# ECD3_MMR_ICONT register map
Vendor: Texas Instruments
Registers are 32-bit, access per field, reset 0x0 unless marked. A register's access mark holds for its fields unless they carry their own. Offsets are as the file gives them; [hi:lo] are bit positions.

## ECD3_MMR_ICONT (part 2 of 2)
0x00 ECD_PID ro reset not defined — Product Identification
  [31:0] PID — Displays the product identification code.
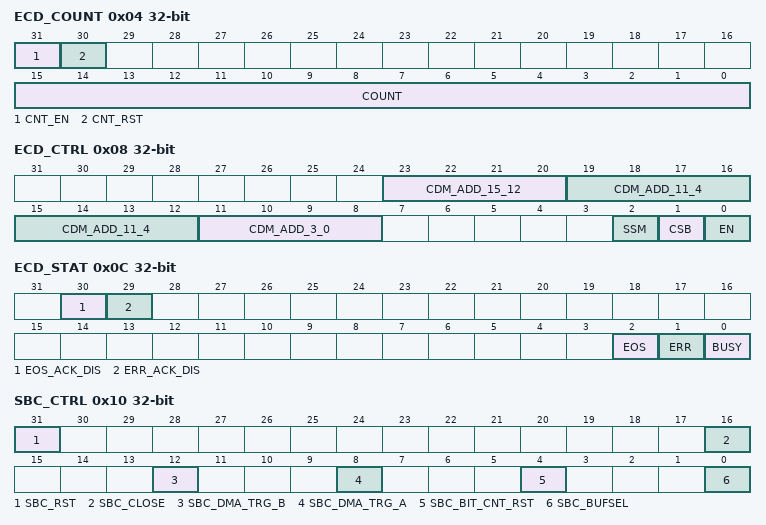
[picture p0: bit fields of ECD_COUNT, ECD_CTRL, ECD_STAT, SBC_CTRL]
0x04 ECD_COUNT — Cycle Counter
  [31] CNT_EN rw — Write 0x0: Disable the cycle counter. Write 0x1: Enable the cycle counter. While ECD_COUNT[31] CNT_EN = 0x1 and ECD_CTRL[0] EN = 0x1, the ECD3 increments the value of ECD_COUNT[15:0] COUNT for each cycle.
  [30] CNT_RST wo — Resets the cycle counter COUNT value to 0. Write 0x1: Clears COUNT. Write 0x0: No effect. Reads returns 0.
  [15:0] COUNT ro — Displays the current counter value.
0x08 ECD_CTRL (reset mask 0xFFFFFFFB) — Control
  [23:20] CDM_ADD_15_12 ro — Specifies the starting byte address [15:12] of command sequence stored in ECDABUF. Note that LSB 4 bits are fixed to 0 since command codes are to be stored from an 16-byte aligned position. ECD3 reads and executes commands in a linear order from this address.
  [19:12] CDM_ADD_11_4 rw — Specifies the starting byte address [11:4] of command sequence stored in ECDABUF. Note that LSB 4 bits are fixed to 0 since command codes are to be stored from an 16-byte aligned position. ECD3 reads and executes commands in a linear order from this address.
  [11:8] CDM_ADD_3_0 ro — Specifies the starting byte address [3:0] of command sequence stored in ECDABUF. Note that LSB 4 bits are fixed to 0 since command codes are to be stored from an 16-byte aligned position. ECD3 reads and executes commands in a linear order from this address.
  [2] SSM rw — 0x1: Enable single command mode. In single command mode, the ECD3 core executes only one command.
  [1] CSB ro — Read 0x1: Indicates that ECD3 found an undefined op-code during the last operation, and aborted command processing. Read 0x0: Indicates that the last command processing ended normally with an END command.
  [0] EN rw — Write 0x1: ECD3 starts operation (command processing), and EN stays 1 until ECD3 ends its operation. When ECD3 ends its operation, EN is turned to 0 by the ECD3. While EN = 1, no write access to ECD_CTRL is allowed. If ECD_CTRL is written while EN = 1, the result is unknown.
0x0C ECD_STAT — ECD Status
  [30] EOS_ACK_DIS rw — Read 0x1: Indicates that the EOS interrupt handshake between ECD3 and SYNCBOX is disabled and the acknowledge signal is ignored. When it is disabled, the ECD3 does not wait for an acknowledge for EOS interrupt. Read 0x0: Indicates that ECD3 waits for an acknowledge from SYNCBOX after EOS is set to 1. The ECD3 stays BUSY state until the acknowledge or EOS is cleared.
  [29] ERR_ACK_DIS rw — Read 0x1: Indicates that the ERR interrupt handshake between ECD3 and SYNCBOX is disabled and the acknowledge signal is ignored. When it is disabled, the ECD3 does not wait for an acknowledge for ERR interrupt. Read 0x0: Indicates that ECD3 waits for an acknowledge from SYNCBOX after ERR is set to 1. The ECD3 stays BUSY state until the acknowledge or ERR is cleared.
  [2] EOS ro — Read 0x1: Indicates that the last macroblock is at the end of the slice. Write 0x0: Force to exit busy state while waiting for an acknowledge of EOS interrupt from SYNCBOX.
  [1] ERR ro — Read 0x1: Indicates an error was found in the stream while decoding. Write 0x0: Force to exit busy state while waiting for an acknowledge of ERR interrupt from SYNCBOX.
  [0] BUSY ro — Read 0x1: Indicates that ECD3 core is busy. This bit is set when EN bit in ECD_CTRL is set and is cleared when END command is executed.
0x10 SBC_CTRL — Stream Buffer Controller Control
  [31] SBC_RST wo — Resets the Stream Buffer Controller. Write 0x1: Resets all registers of Stream Buffer Controller (SBC) and brings it back to idle state. This has the same effect as hardware reset to SBC, but no effect to other part of ECD3 core. Write 0x0: No effect.
  [16] SBC_CLOSE wo — Close the bitstream data. When encoding: Write 0x1: Flushes bitstream data in Stream Buffer. Write 0x0: No effect When decoding: Write 0x1: Brings it back to idle state and discard bitstream data in the buffer. Write 0x0: No effect
  [12] SBC_DMA_TRG_B wo — Start DMA to fill empty page in the Buffer B manually. Write 0x1: Sends a DMA request for Buffer B.
  [8] SBC_DMA_TRG_A wo — Start DMA to fill empty page in the Buffer A manually. Write 0x1: Sends a DMA request for Buffer A.
  [4] SBC_BIT_CNT_RST wo — Reset bit counter in the Stream Buffer.
  [0] SBC_BUFSEL rw — Selects active buffer between A and B: Write 0x0: Buffer A is selected Write 0x1: Buffer B is selected This bit is ignored if SBC_BUFCFG[24] SBC_DBL = 0. If SBC_BUFCFG[24] SBC_DBL = 0, buffer A is always selected.
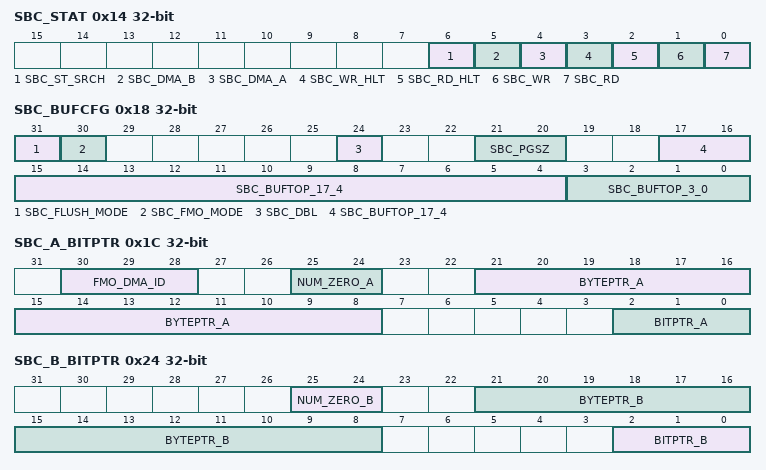
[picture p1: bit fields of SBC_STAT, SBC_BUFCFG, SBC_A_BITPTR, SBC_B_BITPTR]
0x14 SBC_STAT access not given — Stream Buffer Controller Status
  [6] SBC_ST_SRCH ro — Read 0x1: Indicates that the Stream Buffer Controller searching start code by request from codec engine. This bit is cleared when start code is found or page counter value reaches SBC_SRCH_PG_CNT.
  [5] SBC_DMA_B — Read 0x1: Indicates that the Stream Buffer Controller is waiting an acknowledge from DMA for buffer B. Write 0x0: Force to exit busy state while waiting for an acknowledge of DMA for buffer B interrupt from SYNCBOX. (access RW W0toClr)
  [4] SBC_DMA_A — Read 0x1: Indicates that the Stream Buffer Controller is waiting an acknowledge from DMA for buffer A. Write 0x0: Force to exit busy state while waiting for an acknowledge of DMA for buffer A interrupt from SYNCBOX. (access RW W0toClr)
  [3] SBC_WR_HLT ro — Read 0x1: Indicates that the Stream Buffer Controller halted while writing (encoding) and is waiting an acknowledge from DMA. If SBC_WR_HLT = 1, SBC_DMA_A or SBC_DMA_B must also be asserted.
  [2] SBC_RD_HLT ro — Read 0x1: Indicates that the Stream Buffer Controller halted while reading (decoding) and is waiting an acknowledge from DMA.
  [1] SBC_WR ro — Read 0x1: Indicates that the Stream Buffer Controller is in writing (encoding) mode.
  [0] SBC_RD ro — Read 0x1: Indicates that the Stream Buffer Controller is in reading (decoding) mode.
0x18 SBC_BUFCFG — Stream Buffer Controller Buffer Configuration
  [31] SBC_FLUSH_MODE rw — SBC FIFO flush mode select for encoding. Write 0x0: Flush FIFO when EOS flag is sent by Codec Engine Write 0x1: Flush FIFO when DONE or EOS flag is sent by Codec Engine. (This is for debug)
  [30] SBC_FMO_MODE rw — SBC FIFO flush mode select for encoding. Write 0x0: Buffer A and B pointers are used for Stream Data access. SBC_A_BITPTR[30:28] FMO_DMA_ID will be ignored. Write 0x1: Buffer A pointer and SBC_A_BITPTR[30:28] FMO_DMA_ID are used for Stream Data access.
  [24] SBC_DBL rw — Enables double buffer mode. Write 0x0: disabled (buffer A only mode) Write 0x1: enabled (buffer A and buffer B).
  [21:20] SBC_PGSZ rw — Specifies the page size of buffer A and B in the unit of 1024 [byte]. If SBC_PGSZ = 0, it is treated as though SBC_PGSZ = 4 that is, the page size is set to 4096 [byte].
  [17:4] SBC_BUFTOP_17_4 rw — Specifies the base address [17:4] of the bitstream buffer in SL2. Note that the LSB 4 bits are fixed to 0 because of the 128-bit alignment of the buffer area.
  [3:0] SBC_BUFTOP_3_0 ro — Specifies the base address [3:0] of the bitstream buffer in SL2. Note that the LSB 4 bits are fixed to 0 because of the 128-bit alignment of the buffer area.
0x1C SBC_A_BITPTR — Stream Buffer Controller A Bit Pointer
  [30:28] FMO_DMA_ID rw — Indicates the ID number of bitstream data in SL2 memory. The ID number is applied to SBC_FMO_DMA_STAT[7:0] FMO_DMA. This ID is valid when SBC_BUFCFG[30] SBC_FMO_MODE=1.
  [25:24] NUM_ZERO_A rw — Indicates the number of 0 bytes in the past for buffer A. This is used for emulation prevention byte manipulation. Note that the counting 0 bytes in decoding is different from that in encoding. 0 &lt;= NUM_ZERO_A &lt;= 2. This bit field is not updated when JPEG is selected by CDC_MODE. This bit field setting must match with actual bitstream data. If it does not match, EPB or EPC may be inserted or removed wrongly. This bit field is used only for H.264, VC-1 and AVS.
  [21:8] BYTEPTR_A rw — Indicates the current byte offset address in Buffer A of the byte containing the next bit in the bitstream. 0 &lt;= BYTEPTR_A &lt; 2 * (page size).
  [2:0] BITPTR_A rw — Indicates the next bit position in the byte at BYTEPTR_A. 0 &lt;= BITPTR_A &lt;= 7.
0x20 SBC_A_DMAPG — Stream Buffer Controller A DMA Page
  [7:0] DMAPG_A rw — Indicates the page that is being accessed from DMA for bitstream data transferring. If DMA is not accessing to the buffer, this register indicates the page that is currently being accessed from ECD3 core. The state is toggled by DMA task complete acknowledge (ack_strm_a).
0x24 SBC_B_BITPTR — Stream Buffer Controller B Bit Pointer
  [25:24] NUM_ZERO_B rw — Indicates the number of 0 bytes in the past for buffer B. This is used for emulation prevention byte manipulation. Note that the counting 0 bytes in decoding is different from that in encoding. 0 &lt;= NUM_ZERO_B &lt;= 2. This bit field is not updated when JPEG is selected by CDC_MODE. This bit field setting must match with actual bitstream data. If it does not match, EPB or EPC may be inserted or removed wrongly. This bit field is used only for H.264, VC-1 and AVS.
  [21:8] BYTEPTR_B rw — Indicates the current byte offset address in Buffer B of the byte containing the next bit in the bitstream. 0 &lt;= BYTEPTR_B &lt; 2 * (page size).
  [2:0] BITPTR_B rw — Indicates the next bit position in the byte at BYTEPTR_B. 0 &lt;= BITPTR_B &lt;= 7.
0x28 SBC_B_DMAPG — Stream Buffer Controller B DMA Page
  [0] DMAPG_B rw — Indicates the page that is being accessed from DMA for bitstream data transferring. If DMA is not accessing to the buffer, this register indicates the page that is currently being accessed from ECD3 core. This bit is toggled by DMA task complete acknowledge (ack_strm_b).
0x2C SBC_TTLCNT rw — Stream Buffer Controller Total Bit Counter
  [31:0] TTLCNT — Displays the total bit count. This counter does not count during start code searching.
0x30 SBC_RSDCNT rw — Stream Buffer Controller Residual Layer Bit Counter
  [31:0] SBC_RSDCNT — Displays the bit count for residual layer. Total bit count - header info = residual data (transform coefficients)
0x38 SBC_SRCH_PG_CNT — Buffer page counter for start code searching.
  [15:0] SRCH_PG_CNT rw — ECD3 search start code until the page counter reach this number. If the start code is not found, error pulse is sent to codec engine and codec engine stop operation then generates an error interrupt.
0x3C SBC_FMO_DMA_STAT access not given — FMO_DMA status register
  [7:0] FMO_DMA — Indicates FMO_DMA_ID for stream interrupt at buffer page boundary. FMO_DMA_ID range is 0 to 7. When the interrupt is asserted, corresponding bit is set. Write 0 to clear the flag. Writing 1 does not affect this register. (access RW W0toClr)
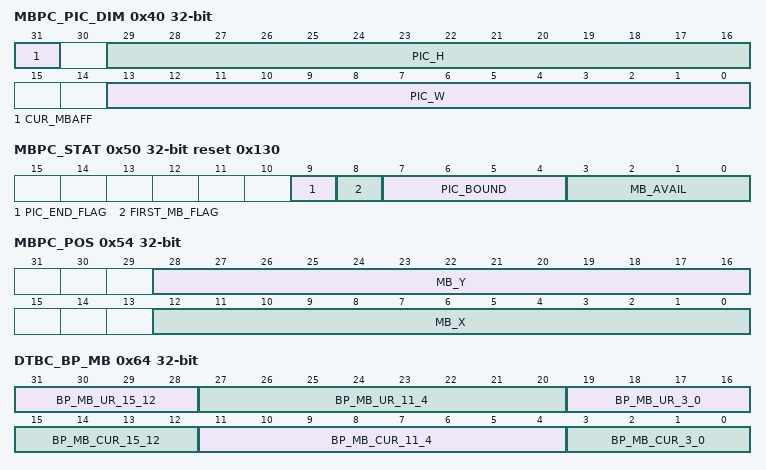
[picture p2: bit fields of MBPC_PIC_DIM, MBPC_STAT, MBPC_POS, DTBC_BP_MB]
0x40 MBPC_PIC_DIM — Picture Dimension
  [31] CUR_MBAFF rw — CUR_MBAFF = 1 indicates that current picture is in H.264 MBAFF mode.
  [29:16] PIC_H rw — PIC_H specifies the picture height in macroblocks which is calculated by PIC_H = ((picture height in pixels) + 15)/16. 0 &lt; PIC_H &lt;= 8192. All codec maximum picture height in pixels is 4096 (PIC_H = 256) except JPEG.
  [13:0] PIC_W rw — PIC_W specifies the picture width in macroblocks which is calculated by PIC_W = ((picture width in pixels) + 15)/16. 0 &lt; PIC_W &lt;= 8192. All codec maximum picture width in pixels is 4096 (PIC_W = 256) except JPEG.
0x50 MBPC_STAT reset 0x130 — MB Position Controller Status
  [9] PIC_END_FLAG rw — PIC_END_FLAG = 1 indicates that the macroblock will be processed is at the end of the picture. (In other words, this field is set to 1 before last MB process execution.)
  [8] FIRST_MB_FLAG rw — FIRST_MB_FLAG = 1 indicates that the macroblock will be processed is the first macroblock in the slice. (In other words, this field is set to 1 after last MB process execution.)
  [7:4] PIC_BOUND rw — PIC_BOUND indicates that the picture boundary status of the current macroblock (in case of MBAFF mode, the unit is macroblock-pair). PIC_BOUND[0] = 1 indicates that the left macroblock edge is an picture boundary. PIC_BOUND[1] = 1 indicates that the upper edge is an picture boundary. PIC_BOUND[2] = 1 indicates that the right edge is an picture boundary. PIC_BOUND[3] = 1 indicates that the bottom edge is an picture boundary.
  [3:0] MB_AVAIL rw — MB_AVAIL indicates that the availabilities of neighboring macroblocks (in case of MBAFF mode, the unit is macroblock-pair). MB_AVAIL[0] : left macroblock, MB_AVAIL[1] : upper left macroblock, MB_AVAIL[2] : upper macroblock, MB_AVAIL[3] :.upper-right macroblock.
0x54 MBPC_POS — Macroblock Position
  [28:16] MB_Y rw — MB_Y equals the macroblock y-position in the picture. 0 &lt;= MB_Y &lt; PIC_H. All codec maximum MB Y position is 255 except JPEG.
  [12:0] MB_X rw — MB_X equals the macroblock x-position in the picture. 0 &lt;= MB_X &lt; PIC_W. All codec maximum MB X position is 255 except JPEG.
0x58 MBPC_PMC — Macroblock Count In Picture
  [25:0] PIC_MB_CNT rw — PIC_MB_CNT equals the macroblock count in the picture. 0 &lt;= PIC_MB_CNT &lt; (PIC_W * PIC_H).
0x5C MBPC_SMC — Macroblock Count In Slice
  [25:0] SLC_MB_CNT rw — SLC_MB_CNT equals the macroblock count in the slice. 0 &lt;= SLC_MB_CNT &lt; (PIC_W * PIC_H).
0x64 DTBC_BP_MB — Data Buffer Controller MB Base Buffer Pointer
  [31:28] BP_MB_UR_15_12 ro — BP_MB_UR specifies the base pointer to the upper macroblock buffer. 0x8000-0x8FFF.
  [27:20] BP_MB_UR_11_4 rw — BP_MB_UR specifies the base pointer to the upper macroblock buffer. 0x8000-0x8FFF.
  [19:16] BP_MB_UR_3_0 ro — BP_MB_UR specifies the base pointer to the upper macroblock buffer. 0x8000-0x8FFF.
  [15:12] BP_MB_CUR_15_12 ro — BP_MB_CUR specifies the base pointer to the current macroblock buffer. 0x8000-0x8FFF.
  [11:4] BP_MB_CUR_11_4 rw — BP_MB_CUR specifies the base pointer to the current macroblock buffer. 0x8000-0x8FFF.
  [3:0] BP_MB_CUR_3_0 ro — BP_MB_CUR specifies the base pointer to the current macroblock buffer. 0x8000-0x8FFF.
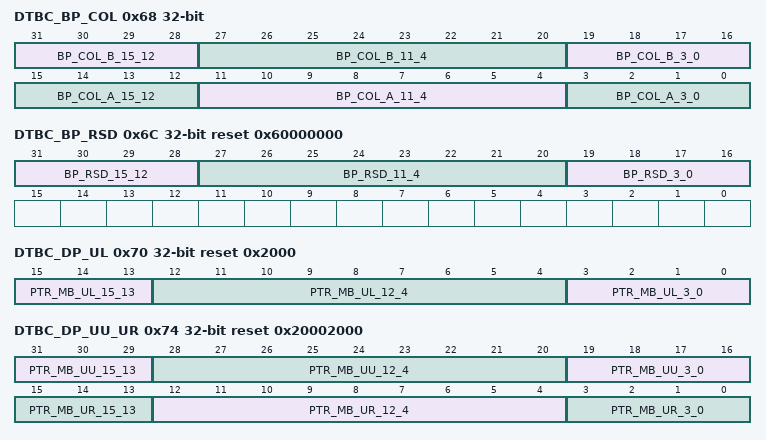
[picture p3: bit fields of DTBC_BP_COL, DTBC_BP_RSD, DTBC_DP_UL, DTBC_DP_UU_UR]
0x68 DTBC_BP_COL — Data Buffer Controller Co-located MB Buffer Base Pointer
  [31:28] BP_COL_B_15_12 ro — BP_COL_B specifies the base pointer to the co-located macroblock buffer B. 0x8000-0x8FFF.
  [27:20] BP_COL_B_11_4 rw — BP_COL_B specifies the base pointer to the co-located macroblock buffer B. 0x8000-0x8FFF.
  [19:16] BP_COL_B_3_0 ro — BP_COL_B specifies the base pointer to the co-located macroblock buffer B. 0x8000-0x8FFF.
  [15:12] BP_COL_A_15_12 ro — BP_COL_A specifies the base pointer to the co-located macroblock buffer A. 0x8000-0x8FFF.
  [11:4] BP_COL_A_11_4 rw — BP_COL_A specifies the base pointer to the co-located macroblock buffer A. 0x8000-0x8FFF.
  [3:0] BP_COL_A_3_0 ro — BP_COL_A specifies the base pointer to the co-located macroblock buffer A. 0x8000-0x8FFF.
0x6C DTBC_BP_RSD reset 0x60000000 — Data Buffer Controller Residual Buffer Base Pointer
  [31:28] BP_RSD_15_12 ro — BP_RSD specifies the base pointer to the residual data buffer. 0xE000-0xEFFF.
  [27:20] BP_RSD_11_4 rw — BP_RSD specifies the base pointer to the residual data buffer. 0xE000-0xEFFF.
  [19:16] BP_RSD_3_0 ro — BP_RSD specifies the base pointer to the residual data buffer. 0xE000-0xEFFF.
0x70 DTBC_DP_UL reset 0x2000 — Data Buffer Controller Data Pointer 0
  [15:13] PTR_MB_UL_15_13 ro — Current pointer [15:13] to the upper left macroblock data in work buffer. This pointer must be written before start ECD3.
  [12:4] PTR_MB_UL_12_4 rw — Current pointer [12:4] to the upper left macroblock data in work buffer. This pointer must be written before start ECD3.
  [3:0] PTR_MB_UL_3_0 ro — Current pointer [3:0] to the upper left macroblock data in work buffer. This pointer must be written before start ECD3.
0x74 DTBC_DP_UU_UR reset 0x20002000 — Data Buffer Controller Data Pointer 1
  [31:29] PTR_MB_UU_15_13 ro — Current pointer [15:13] to the upper macroblock data in work buffer. This pointer must be written before start ECD3.
  [28:20] PTR_MB_UU_12_4 rw — Current pointer [12:4] to the upper macroblock data in work buffer. This pointer must be written before start ECD3.
  [19:16] PTR_MB_UU_3_0 ro — Current pointer [3:0] to the upper macroblock data in work buffer. This pointer must be written before start ECD3.
  [15:13] PTR_MB_UR_15_13 ro — Current pointer [15:13] to the upper-right macroblock data in work buffer. This pointer must be written before start ECD3.
  [12:4] PTR_MB_UR_12_4 rw — Current pointer [12:4] to the upper-right macroblock data in work buffer. This pointer must be written before start ECD3.
  [3:0] PTR_MB_UR_3_0 ro — Current pointer [3:0] to the upper-right macroblock data in work buffer. This pointer must be written before start ECD3.
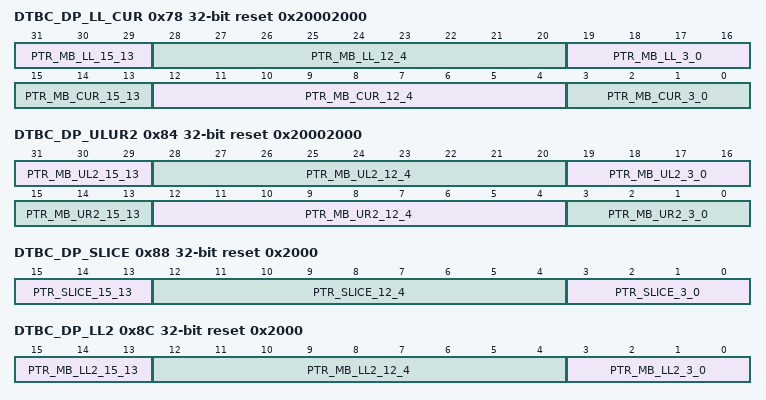
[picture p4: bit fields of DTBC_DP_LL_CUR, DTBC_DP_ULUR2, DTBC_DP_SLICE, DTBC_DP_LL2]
0x78 DTBC_DP_LL_CUR reset 0x20002000 — Data Buffer Controller Data Pointer 2
  [31:29] PTR_MB_LL_15_13 ro — Current pointer [15:13] to the left macroblock data in work buffer. This pointer must be written before start ECD3.
  [28:20] PTR_MB_LL_12_4 rw — Current pointer [12:4] to the left macroblock data in work buffer. This pointer must be written before start ECD3.
  [19:16] PTR_MB_LL_3_0 ro — Current pointer [3:0] to the left macroblock data in work buffer. This pointer must be written before start ECD3.
  [15:13] PTR_MB_CUR_15_13 ro — Current pointer [15:13] to the current macroblock data in work buffer. This pointer must be written before start ECD3.
  [12:4] PTR_MB_CUR_12_4 rw — Current pointer [12:4] to the current macroblock data in work buffer. This pointer must be written before start ECD3.
  [3:0] PTR_MB_CUR_3_0 ro — Current pointer [3:0] to the current macroblock data in work buffer. This pointer must be written before start ECD3.
0x84 DTBC_DP_ULUR2 reset 0x20002000 — Data Buffer Controller Data Pointer 5
  [31:29] PTR_MB_UL2_15_13 ro — Current pointer [15:13] to the macroblock left to the upper left macroblock data in work buffer. This pointer is maintained only for On2 (CDC_mode[3:0] MODE = 0x0A). This pointer must be written before start ECD3.
  [28:20] PTR_MB_UL2_12_4 rw — Current pointer [12:4] to the macroblock left to the upper left macroblock data in work buffer. This pointer is maintained only for On2 (CDC_mode[3:0] MODE = 0x0A). This pointer must be written before start ECD3.
  [19:16] PTR_MB_UL2_3_0 ro — Current pointer [3:0] to the macroblock left to the upper left macroblock data in work buffer. This pointer is maintained only for On2 (CDC_mode[3:0] MODE = 0x0A). This pointer must be written before start ECD3.
  [15:13] PTR_MB_UR2_15_13 ro — Current pointer [15:13] to the macroblock right to the upper-right macroblock data in work buffer. This pointer is maintained only for On2 (CDC_mode[3:0] MODE = 0x0A). This pointer must be written before start ECD3.
  [12:4] PTR_MB_UR2_12_4 rw — Current pointer [12:4] to the macroblock right to the upper-right macroblock data in work buffer. This pointer is maintained only for On2 (CDC_mode[3:0] MODE = 0x0A). This pointer must be written before start ECD3.
  [3:0] PTR_MB_UR2_3_0 ro — Current pointer [3:0] to the macroblock right to the upper-right macroblock data in work buffer. This pointer is maintained only for On2 (CDC_mode[3:0] MODE = 0x0A). This pointer must be written before start ECD3.
0x88 DTBC_DP_SLICE reset 0x2000 — Slice data pointer
  [15:13] PTR_SLICE_15_13 ro — Specifies the pointer [15:13] to slice or picture information data.
  [12:4] PTR_SLICE_12_4 rw — Specifies the pointer [12:4] to slice or picture information data.
  [3:0] PTR_SLICE_3_0 ro — Specifies the pointer [3:0] to slice or picture information data.
0x8C DTBC_DP_LL2 reset 0x2000 — Data Buffer Controller data pointer
  [15:13] PTR_MB_LL2_15_13 ro — Current pointer [15:13] to the macroblock left to the left macroblock data in work buffer. This pointer is maintained only for On2 (CDC_mode[3:0] MODE = 0x0A). This pointer must be written before start ECD3.
  [12:4] PTR_MB_LL2_12_4 rw — Current pointer [12:4] to the macroblock left to the left macroblock data in work buffer. This pointer is maintained only for On2 (CDC_mode[3:0] MODE = 0x0A). This pointer must be written before start ECD3.
  [3:0] PTR_MB_LL2_3_0 ro — Current pointer [3:0] to the macroblock left to the left macroblock data in work buffer. This pointer is maintained only for On2 (CDC_mode[3:0] MODE = 0x0A). This pointer must be written before start ECD3.
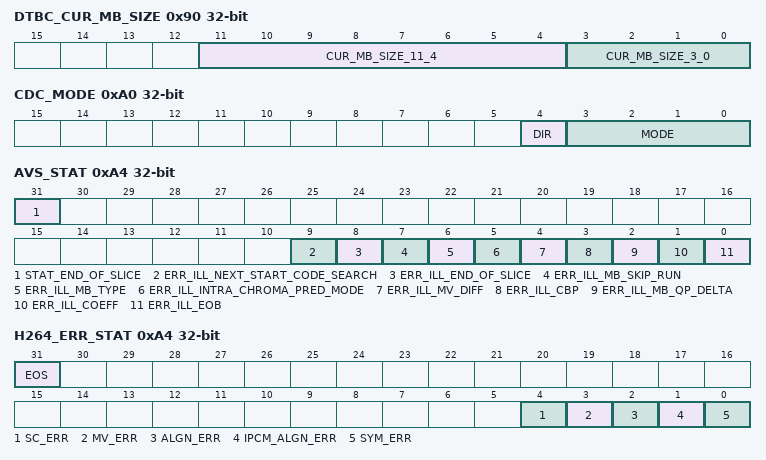
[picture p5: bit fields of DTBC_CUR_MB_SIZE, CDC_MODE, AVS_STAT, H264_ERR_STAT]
0x90 DTBC_CUR_MB_SIZE — Current Picture Macro Block element size
  [11:4] CUR_MB_SIZE_11_4 rw — Data element size for Current MB, Upper-right MB in AUX buffer and Upper MB, Current/Left MB in WORK buffer.
  [3:0] CUR_MB_SIZE_3_0 ro — Data element size for Current MB, Upper-right MB in AUX buffer and Upper MB, Current/Left MB in WORK buffer.
0xA0 CDC_MODE — Codec Mode (also works as view page).
  [4] DIR rw — Selects the codec direction: Write 0x0: Indicates the codec engine is decoding Write 0x1: Indicates the codec engine is encoding.
  [3:0] MODE rw — Selects the active codec Selected Codec (Selected Codec Engine)
    0=JPEG_(JPG); 1=N/A; 2=MPEG-1_(MP1); 3=MPEG-2_(MP2); 4=MPEG-4/H.263_(MP4); 5=VC-1_Advanced_(VC-1); 6=H.264_(H.264); 7=VC-1_Simple/Main_(VC-1); 8=AVS_(AVS); 9=RealVideo_(RV); 10=On2_VP6,VP7_(On2)
0xA4 AVS_STAT ro
  [31] STAT_END_OF_SLICE — stat_end_of_vop ECD sets this field to 1 when the current macroblock is the last macroblock in a VOP Once this field is set, ECD keeps this field to 1 until the next macroblock processing is started. ECD resets this field at the beginning of a macroblock processing
  [9] ERR_ILL_NEXT_START_CODE_SEARCH — err_ill_next_start_code_search If ECD founds error and ECD status is changed into ERR in error detection described in section 8.5., ECD starts to search the next start code search. But if ECD cannot find the start code until search counter reaches counter limit defined in the ECD3 core MMR, ECD fails start_code_search. In this case this flag is set to 1 by ECD; otherwise, 0
  [8] ERR_ILL_END_OF_SLICE — err_ill_end_of_slice Some encoder wrongly encode EOS. In this case this flag is set to 1 by ECD; otherwise, 0
  [7] ERR_ILL_MB_SKIP_RUN — err_ill_mb_skip_run If ECD founds decoded mb_skip_run is out of range, this field is set to 1 by ECD; otherwise, 0
  [6] ERR_ILL_MB_TYPE — err_ill_mb_type If ECD founds decoded mb_type is out of range, this field is set to 1 by ECD; otherwise, 0
  [5] ERR_ILL_INTRA_CHROMA_PRED_MODE — err_ill_intra_chroma_pred_mode If ECD founds decoded intra_chroma_pred_mode is out of range, this field is set to 1 by ECD; otherwise, 0
  [4] ERR_ILL_MV_DIFF — err_ill_mv_diff If ECD founds decoded mv_diff is out of range, this field is set to 1 by ECD; otherwise, 0
  [3] ERR_ILL_CBP — err_ill_cbp If ECD founds decoded cbp is out of range, this field is set to 1 by ECD; otherwise, 0
  [2] ERR_ILL_MB_QP_DELTA — err_ill_mb_qp_delta If ECD founds decoded mb_qp_delta is out of range, this field is set to 1 by ECD; otherwise, 0.
  [1] ERR_ILL_COEFF — err_ill_coeff If ECD founds decoded coefficient is out of range, this field is set to 1 by ECD; otherwise, 0
  [0] ERR_ILL_EOB — err_ill_eob If ECD cannot found end of block in 64 coefficients, this field is set to 1 by ECD; otherwise, 0.
0xA4 H264_ERR_STAT ro — H.264 STAT register
  [31] EOS — Read 0x1: Indicates that an EOS was found
  [4] SC_ERR — Read 0x1: Indicates that there was an error while searching the next start code. This error can only occur at the EOS where EOS=1.
  [3] MV_ERR — Read 0x1: Indicates that motion vector error was found in the last B-Direct motion vector calculation
  [2] ALGN_ERR — Read 0x1: Indicates that a zero bit was found in the last CABAC alignment bits
  [1] IPCM_ALGN_ERR — Read 0x1: Indicates that a non-zero bit was found in the last I_PCM alignment bits
  [0] SYM_ERR — Read 0x1: Indicates an illegal code word was found in the bitstream
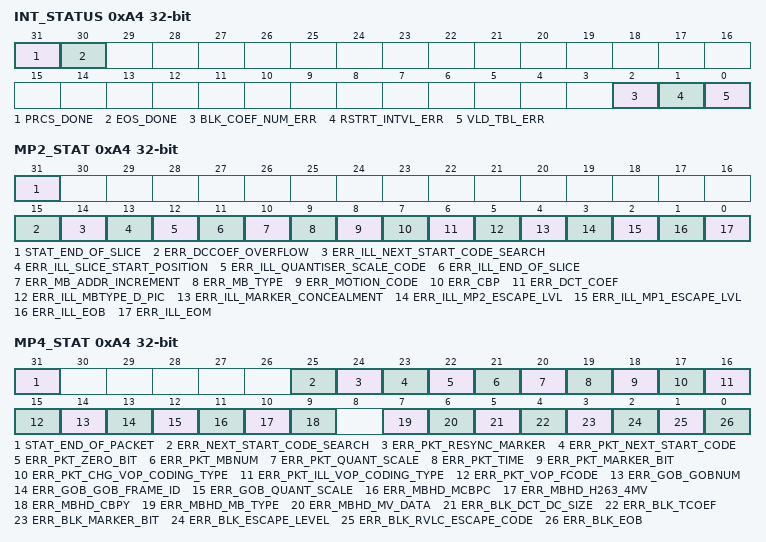
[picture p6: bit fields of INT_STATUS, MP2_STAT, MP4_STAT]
0xA4 INT_STATUS ro — INT STAT register
  [31] PRCS_DONE — If encoding or decoding of a picture is finished, an interrupt pulse is asserted and this status bit becomes high. It makes no sense to write 0 to this register bit. 0: not finished. 1: processing done
  [30] EOS_DONE — If encoding of decoding of a scan is finished, an interrupt pulse is asserted and this status bit becomes high. It makes no sense to write 0 to this register bit. 0: not finished. 1: processing done
  [2] BLK_COEF_NUM_ERR — If current MCU has a block which has more than 64 coefficients, this error bit becomes high. 0: correct (all blocks inside the current MCU have 64[coef/block]) 1: incorrect (some blocks inside the current MCU have more than 64[coef/block]).
  [1] RSTRT_INTVL_ERR — If number of MCU between neighbored restart markers is not equal to restart interval, this error bit becomes high. It makes no sense to write 0 to this register bit. 0: no error. 1: restart interval error occurs
  [0] VLD_TBL_ERR — If stream data which is out of table is detected, the JPEG core makes this bit high. It makes no sense to write 0 to this register bit. 0: no error. 1: out of table error occurs.
0xA4 MP2_STAT ro
  [31] STAT_END_OF_SLICE — Showing the current macroblock is the last macroblock in a slice. If STAT_END_OF_SLICE is set to 1, the ECD3 issues int_eos. Host can know whether ERR_ILL_NEXT_START_CODE_SEARCH and ERR_ILL_END_OF_SLICE are happened or not by looking MP2_STAT[14] and MP2_STAT[11] register fields when int_eos is issued.
  [15] ERR_DCCOEF_OVERFLOW — Showing the result of dc prediction is overflowed or under flowed
  [14] ERR_ILL_NEXT_START_CODE_SEARCH — Showing next start code searching infinite error. In decoding, next start code searching is started when: - the current macroblock is the last macroblock in a slice or - error is found w/start_code_search_flag is 1. During next start code searching, if search counter is over the limit of the counter, this field is set to 1. In encoding, this field is fixed to 0.
  [13] ERR_ILL_SLICE_START_POSITION — In decoding, showing the following two data is mismatched: - macroblock position derived from slice_vertical_position and macroblock_address_increment - macroblock position in ECD MMR In encoding, this field is fixed to 0.
  [12] ERR_ILL_QUANTISER_SCALE_CODE — In decoding, decoded quantizer_scale_code is 0. In encoding, this field is fixed to 0
  [11] ERR_ILL_END_OF_SLICE — In decoding, EOS cannot be found at the end of picture. In encoding, this field is fixed to 0.
  [10] ERR_MB_ADDR_INCREMENT — In decoding, VLD out of table in macroblock_address_increment. In encoding, this field is fixed to 0.
  [9] ERR_MB_TYPE — In decoding, VLD out of table in macroblock_type. In encoding, this field is fixed to 0.
  [8] ERR_MOTION_CODE — In decoding, VLD out of table in motion_code and dmv. In encoding, this field is fixed to 0.
  [7] ERR_CBP — In decoding, VLD out of table in coded_block_pattern. In encoding, this field is fixed to 0.
  [6] ERR_DCT_COEF — In decoding, VLD out of table in DCT coefficient. In encoding, this field is fixed to 0.
  [5] ERR_ILL_MBTYPE_D_PIC — In decoding, decoded macroblock_type != 1 when D-picture. In encoding, this field is fixed to 0.
  [4] ERR_ILL_MARKER_CONCEALMENT — In decoding, decoded marker_bit != 0 when both the concealment_motion_vector and macroblock_intra are equal to 1. In encoding, this field is fixed to 0.
  [3] ERR_ILL_MP2_ESCAPE_LVL — In decoding, decoded level from MPEG-2 ESCAPE code is 0x000 or 0x800. In encoding, this field is fixed to 0
  [2] ERR_ILL_MP1_ESCAPE_LVL — In decoding, decoded level from MPEG-1 ESCAPE code is 0x0000 or 0x8000. In encoding, this field is fixed to 0.
  [1] ERR_ILL_EOB — In decoding, ECD cannot find EOB, end of block, in a 64 coefficient block. In encoding, this field is fixed to 0.
  [0] ERR_ILL_EOM — In decoding, ECD cannot find EOM, end of macroblock, at the end of macroblock when picture_type is D-picture. In encoding, this field is fixed to 0.
0xA4 MP4_STAT ro
  [31] STAT_END_OF_PACKET — ECD sets this field to 1 when the current macroblock is the last macroblock in a packet. In the case of data partitioned, ECD issues the last macroblock of data partition 0, 1 and 2. Here, data partition 0 means the motion and header info processing, data partition 1 means texture header processing, and data partition 2 means the TCOEF processing. ECD resets this field at the beginning of a macroblock processing
  [25] ERR_NEXT_START_CODE_SEARCH — ECD sets this field to 1 if next start code search is 'failed'. 'Failed' means during next start code search, the search counter is over the limit of the counter which is in ECD3 SBC MMRs. Otherwise, ECD3 sets this field to 0. ECD sets this field the search counter is over the limit of the counter, this field is set to 1. Otherwise, 0.
  [24] ERR_PKT_RESYNC_MARKER — ECD sets this field to 1 when resync_marker at the beginning of packet header is incorrect. At the beginning of a processing, ECD automatically reset this field to 0. Even if ECD detects this error, ECD continues decoding until finishing the current macroblock processing
  [23] ERR_PKT_NEXT_START_CODE — ECD sets this field to 1 when next_start_code at the end of VOP is incorrect or start_code at the beginning of slice or at the end of VOP is incorrect. At the beginning of a processing, ECD automatically reset this field to 0. Even if ECD detects this error, ECD continues decoding until finishing the current macroblock processing
  [22] ERR_PKT_ZERO_BIT — ECD sets this field to 1 when zero_bit at the end of GOB or slice layer is incorrect or emulation_prevention_bit in slice header is incorrect. At the beginning of a processing, ECD automatically reset this field to 0. Even if ECD detects this error, ECD continues decoding until finishing the current macroblock processing
  [21] ERR_PKT_MBNUM — ECD sets this field to 1 when macroblock_number in packet header is dropped. At the beginning of a processing, ECD automatically reset this field to 0. Even if ECD detects this error, ECD continues decoding until finishing the current macroblock processing
  [20] ERR_PKT_QUANT_SCALE — ECD sets this field to 1 when quant_scale in packet header is illegal. At the beginning of a processing, ECD automatically reset this field to 0. Even if ECD detects this error, ECD continues decoding until finishing the current macroblock processing
  [19] ERR_PKT_TIME — ECD sets this field to 1 when modulo_time or vop_time_increment in packet header is changed. At the beginning of a processing, ECD automatically reset this field to 0. Even if ECD detects this error, ECD continues decoding until finishing the current macroblock processing
  [18] ERR_PKT_MARKER_BIT — ECD sets this field to 1 when marker_bit in packet header is incorrect. At the beginning of a processing, ECD automatically reset this field to 0. Even if ECD detects this error, ECD continues decoding until finishing the current macroblock processing
  [17] ERR_PKT_CHG_VOP_CODING_TYPE — ECD sets this field to 1 when vop_coding_type in packet header is changed. At the beginning of a processing, ECD automatically reset this field to 0. Even if ECD detects this error, ECD continues decoding until finishing the current macroblock processing
  [16] ERR_PKT_ILL_VOP_CODING_TYPE — ECD sets this field to 1 when vop_coding_type in packet header is illegal. At the beginning of a processing, ECD automatically reset this field to 0. Even if ECD detects this error, ECD continues decoding until finishing the current macroblock processing
  [15] ERR_PKT_VOP_FCODE — ECD sets this field to 1 when vop_fcode_forward or vop_fcode_backward in packet header is illegal. At the beginning of a processing, ECD automatically reset this field to 0. Even if ECD detects this error, ECD continues decoding until finishing the current macroblock processing
  [14] ERR_GOB_GOBNUM — ECD sets this field to 1 when gob_number is dropped or macroblock_address in slice header is dropped. At the beginning of a processing, ECD automatically reset this field to 0. Even if ECD detects this error, ECD continues decoding until finishing the current macroblock processing
  [13] ERR_GOB_GOB_FRAME_ID — ECD sets this field to 1 when gob_frame_id is changed. At the beginning of a processing, ECD automatically reset this field to 0. Even if ECD detects this error, ECD continues decoding until finishing the current macroblock processing
  [12] ERR_GOB_QUANT_SCALE — ECD sets this field to 1 when quant_scale in GOB header is illegal or slice_quantizer_information in slice header is illegal. At the beginning of a processing, ECD automatically resets this field to 0. Even if ECD detects this error, ECD continues decoding until finishing the current macroblock processing
  [11] ERR_MBHD_MCBPC — ECD sets this field to 1 when mcbpc code is illegal. At the beginning of a processing, ECD automatically reset this field to 0. If ECD detects this error, if data_partitioned is ON, ECD continues decoding the current DP0 or DP1 processing; otherwise, ECD stops decoding and immediately terminates the current macroblock processing
  [10] ERR_MBHD_H263_4MV — ECD3 sets this field to 1 if one of the following two conditions is true: - H263_mode is ON, deblocking_filter_mode = 0, no_gob_header = 0, and decoded macroblock type is INTRA4V or INTRA4V_Q. - H263_mode is ON, deblocking_filter_mode = 1 and decoded macroblock type is INTRA4V_Q. - H.263_mode is ON, no_gob_header=1, and decoded macroblock type is INTRA4V_Q. If ECD detects this error, ECD stops decoding and immediately terminates the current macroblock processing
  [9] ERR_MBHD_CBPY — ECD sets this field to 1 when cpby code is illegal (non-B-VOP). At the beginning of a processing, ECD automatically reset this field to 0. If ECD detects this error, if data_partitioned is ON, ECD continues decoding the current DP0 or DP1 processing; otherwise, ECD stops decoding and immediately terminates the current macroblock processing
  [7] ERR_MBHD_MB_TYPE — ECD sets this field to 1 when mb_type code is illegal (B-VOP). At the beginning of a processing, ECD automatically reset this field to 0. If ECD detects this error, ECD stops decoding and immediately finishes the current macroblock processing
  [6] ERR_MBHD_MV_DATA — ECD sets this field to 1 when horizontal_mv_data or vertical_mv_data code is illegal. At the beginning of a processing, ECD automatically reset this field to 0. If ECD detects this error, if data_partitioned is ON, ECD continues decoding the current DP0 or DP1 processing; otherwise, ECD stops decoding and immediately terminates the current macroblock processing
  [5] ERR_BLK_DCT_DC_SIZE — ECD sets this field to 1 when dct_dc_size code is illegal. At the beginning of a processing, ECD automatically reset this field to 0. If ECD detects this error, if data_partitioned is ON, ECD continues decoding the current DP0 or DP1 processing; otherwise, ECD stops decoding and immediately terminates the current macroblock processing
  [4] ERR_BLK_TCOEF — ECD sets this field to 1 when tcoef code is illegal. At the beginning of a processing, ECD automatically reset this field to 0. If ECD detects this error, ECD stops decoding and immediately finishes the current macroblock processing
  [3] ERR_BLK_MARKER_BIT — ECD sets this field to 1 when marker_bit in dct_dc_size, ESCAPE3 or RVLC is incorrect. At the beginning of a processing, ECD automatically reset this field to 0. If ECD detects this error, if data_partitioned is ON and the error is in marker_bit of dct_dc_size, ECD continues decoding the current DP0 or DP1 processing; otherwise, ECD continues decoding until finishing the current macroblock decoding
  [2] ERR_BLK_ESCAPE_LEVEL — ECD sets this field to 1 when ESCAPE3 level = 0 or 0x800, RVLC ESCAPE level = 0, H.263 DC = 0x00 or 0x80 or H.263 ESCAPE level = 0 or 0x80. At the beginning of a processing, ECD automatically reset this field to 0. If ECD detects this error, ECD stops decoding and immediately terminates the current macroblock processing
  [1] ERR_BLK_RVLC_ESCAPE_CODE — ECD sets this field to 1 when the last ESCAPE code of RVLC ESCAPE is not '0000s'. At the beginning of a processing, ECD automatically reset this field to 0. If ECD detects this error, ECD stops decoding and immediately terminates the current macroblock processing
  [0] ERR_BLK_EOB — ECD sets this field to 1 when ECD cannot find EOB in 64 coefficients. At the beginning of a processing, ECD automatically reset this field to 0. If ECD detects this error, ECD stops decoding and immediately finishes the current macroblock processing
